# HSI_DMA_CHANNELS register map
Vendor: Texas Instruments
Peripheral module from a debugger description file (folder omap5430_ES2_PUBLIC).
Registers are 32-bit, access per field, reset 0x0 unless marked. A register's access mark holds for its fields unless they carry their own. Offsets are as the file gives them; lines under a group give offsets from that group; [hi:lo] are bit positions; {n}, {i} and the like mark numbered series; 'fields as' and 'values as' point back to an identical list; <NAME> marks a mode.

## HSI_DMA_CHANNELS
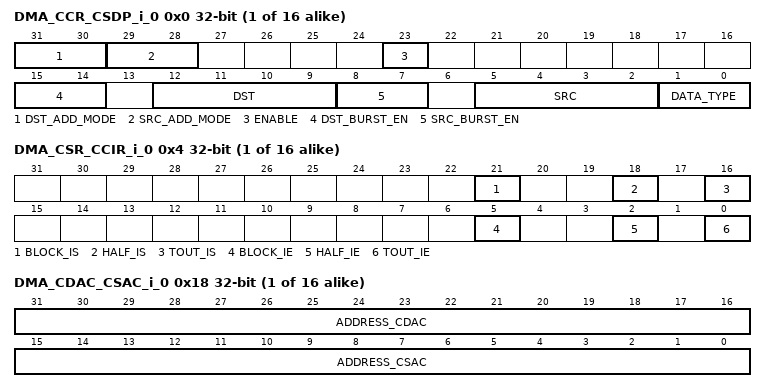
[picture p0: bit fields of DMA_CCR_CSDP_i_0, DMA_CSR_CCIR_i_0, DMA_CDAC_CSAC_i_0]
{0x0+0x40*i} DMA_CCR_CSDP_i_{i} (i=0..15) — Stores source and destination parameters and channel control bits
  [31:30] DST_ADD_MODE rw — Destination addressing mode
    0=Constant_address; 1=Post-increment_address
  [29:28] SRC_ADD_MODE rw — Source addressing mode
    0=Constant_address; 1=Post-increment_address
  [23] ENABLE rw — Logical channel enable
    0=Transfer_stops_and_is_reset; 1=Transfer is enabled. Automatically cleared by hardware once transfer is finished.
  [15:14] DST_BURST_EN rw — Destination burst enable
    0=Single_access; 1=Single_access; 3=Burst_8_×_32_bits_(not_implemented); 2=Burst_4_×_32_bits
  [12:9] DST rw — Transfer destination
    8=Transfer_to_memory_port; 9=Transfer_to_peripheral_port
  [8:7] SRC_BURST_EN rw — Source burst enable
    values as DST_BURST_EN
  [5:2] SRC rw — Transfer source
    8=Transfer_from_memory_port; 9=Transfer_from_peripheral_port
  [1:0] DATA_TYPE rw — Defines data types Implemented bit field but not used
{0x4+0x40*i} DMA_CSR_CCIR_i_{i} (i=0..15) — Interrupt enable and status register Interrupt flag fields will be cleared through read access using the following byte-enable values: 0xC 0xF
  [21] BLOCK_IS ro — Block transferred
    1=Block_transferred; 0=No_event
  [18] HALF_IS ro — Half block reached
    1=Half-block_transferred; 0=No_event
  [16] TOUT_IS ro — Time-out overflow event
    1=Time-out_occurred; 0=No_event
  [5] BLOCK_IE rw — Interrupt is sent when a full block is transferred
    0=No_interrupt; 1=Interrupt_enable
  [2] HALF_IE rw — Interrupt is sent when a half block is transferred
    0=No_interrupt; 1=Interrupt_enable
  [0] TOUT_IE rw — Interrupt is sent when a time-out overflow occurs
    0=No_interrupt; 1=Interrupt_enable
{0x8+0x40*i} DMA_CSSA_i_{i} rw (i=0..15) — Stores source start address If the transfer configured from memory port, all bits are taken into account as an address. If the transfer configured from peripheral port, the lower 4 bits will determine the FIFO ID.
  [31:0] ADDR — Source start address
{0xC+0x40*i} DMA_CDSA_i_{i} rw (i=0..15) — Stores destination start address If the transfer configured to memory port, all bits are taken into account as an address. If the transfer configured to peripheral port, the lower 4 bits will determine the FIFO ID.
  [31:0] ADDR — Destination start address
{0x10+0x40*i} DMA_CEN_i_{i} (i=0..15) — Stores the number of 4-byte words in a DMA data block. Maximum is 65,536.
  [15:0] SIZE rw — Number of elements in a block. Maximum is 65,536.
{0x18+0x40*i} DMA_CDAC_CSAC_i_{i} ro (i=0..15) — Monitors the progress of DMA transfer, by storing the 16-bit counter address for source and destination.
  [31:16] ADDRESS_CDAC — Destination address
  [15:0] ADDRESS_CSAC — Source address
